# platform_designer_hps_system_hps_0_hps register map
Vendor: default_vendor.com; File version: 0.0
Registers are 32-bit, read-write, reset 0x0 unless marked. A register's access mark holds for its fields unless they carry their own. Offsets are from the block's base; [hi:lo] are bit positions; {n}, {i} and the like mark numbered series; 'fields as' and 'values as' point back to an identical list.

## qspiregs — Registers in the QSPI Flash Controller module accessible via its APB slave
Base 0xFF705000
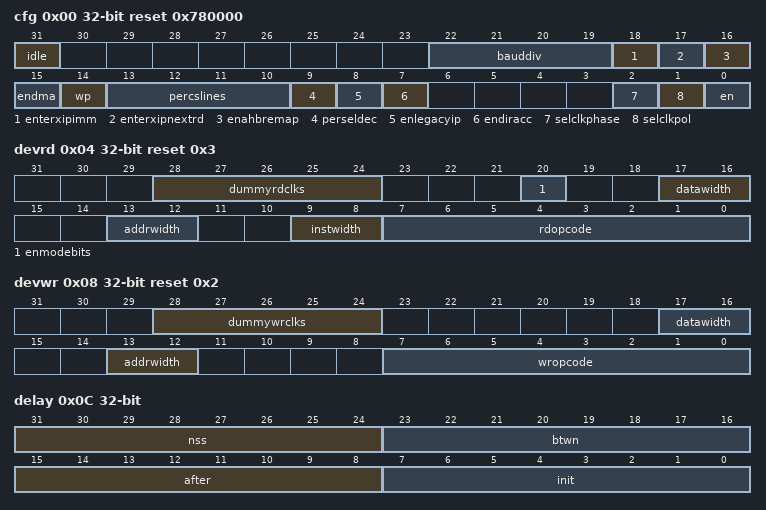
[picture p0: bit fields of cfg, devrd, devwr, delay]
0x00 cfg reset 0x780000
  [31] idle ro — This is a STATUS read-only bit. Note this is a retimed signal, so there will be some inherent delay on the generation of this status signal.
    1=set; 0=notset
  [22:19] bauddiv — SPI baud rate = ref_clk / (2 * baud_rate_divisor)
    0=baud2; 1=baud4; 2=baud6; 3=baud8; 4=baud10; 5=baud12; 6=baud14; 7=baud16; 8=baud18; 9=baud20; 10=baud22; 11=baud24; 12=baud26; 13=baud28; 14=baud30; 15=baud32
  [18] enterxipimm — If XIP is enabled, then setting to disabled will cause the controller to exit XIP mode on the next READ instruction. If XIP is disabled, then setting enable will operate the device in XIP mode immediately. Use this register when the external device wakes up in XIP mode (as per the contents of its non- volatile configuration register). The controller will assume the next READ instruction will be passed to the device as an XIP instruction, and therefore will not require the READ opcode to be transferred. Note: To exit XIP mode, this bit should be set to 0. This will take effect in the attached device only after the next READ instruction is executed. Software therefore should ensure that at least one READ instruction is requested after resetting this bit in order to be sure that XIP mode is exited.
    1=enable; 0=disable
  [17] enterxipnextrd — If XIP is enabled, then setting to disabled will cause the controller to exit XIP mode on the next READ instruction. If XIP is disabled, then setting to enabled will inform the controller that the device is ready to enter XIP on the next READ instruction. The controller will therefore send the appropriate command sequence, including mode bits to cause the device to enter XIP mode. Use this register after the controller has ensured the FLASH device has been configured to be ready to enter XIP mode. Note : To exit XIP mode, this bit should be set to 0. This will take effect in the attached device only AFTER the next READ instruction is executed. Software should therefore ensure that at least one READ instruction is requested after resetting this bit before it can be sure XIP mode in the device is exited.
    1=enable; 0=disable
  [16] enahbremap — (Direct Access Mode Only) When enabled, the incoming AHB address will be adapted and sent to the FLASH device as (address + N), where N is the value stored in the remap address register.
    1=enable; 0=disable
  [15] endma — Allows DMA handshaking mode. When enabled the QSPI will trigger DMA transfer requests via the DMA peripheral interface.
    1=enable; 0=disable
  [14] wp — This bit controls the write protect pin of the flash devices. The signal qspi_mo2_wpn needs to be resynchronized to the generated memory clock as necessary.
    1=wrproton; 0=wrtprotoff
  [13:10] percslines — Peripheral chip select line output decode type. As per perseldec, if perseldec = 0, the decode is select 1 of 4 decoding on signals, qspi_n_ss_out[3:0], The asserted decode line goes to 0. If perseldec = 1, the signals qspi_n_ss_out[3:0] require an external 4 to 16 decoder.
  [9] perseldec — Select between '1 of 4 selects' or 'external 4-to-16 decode'. The qspi_n_ss_out[3:0] output signals are controlled.
    1=sel4to16; 0=sel1of4
  [8] enlegacyip — This bit can select the Direct Access Controller/Indirect Access Controller or legacy mode.If legacy mode is selected, any write to the controller via the AHB interface is serialized and sent to the FLASH device. Any valid AHB read will pop the internal RX-FIFO, retrieving data that was forwarded by the external FLASH device on the SPI lines, byte transfers of 4, 2 or 1 are permitted and controlled via the HSIZE input.
    1=legmode; 0=dimode
  [7] endiracc — If disabled, the Direct Access Controller becomes inactive once the current transfer of the data word (FF_W) is complete. When the Direct Access Controller and Indirect Access Controller are both disabled, all AHB requests are completed with an error response.
    0=disable; 1=enable
  [2] selclkphase — Selects whether the clock is in an active or inactive phase outside the SPI word.
    0=active; 1=inactive
  [1] selclkpol — Controls spiclk modes of operation.
    1=low; 0=high
  [0] en — If this bit is disabled, the QSPI will finish the current transfer of the data word (FF_W) and stop sending. When Enabled, and qspi_n_mo_en = 0, all output enables are inactive and all pins are set to input mode.
    0=disable; 1=enable
0x04 devrd reset 0x3
  [28:24] dummyrdclks — Number of dummy clock cycles required by device for read instruction.
  [20] enmodebits — If this bit is set, the mode bits as defined in the Mode Bit Configuration register are sent following the address bytes.
    0=noorder; 1=order
  [17:16] datawidth — Sets read data transfer width (1, 2, or 4 bits).
    0=single; 1=dual; 2=quad
  [13:12] addrwidth — Sets read address transfer width (1, 2, or 4 bits).
    0=single; 1=dual; 2=quad
  [9:8] instwidth — Sets instruction transfer width (1, 2, or 4 bits). Applies to all instructions sent to SPI flash device (not just read instructions).
    0=single; 1=dual; 2=quad
  [7:0] rdopcode — Read Opcode to use when not in XIP mode
    3=read; 11=fastread
0x08 devwr reset 0x2
  [28:24] dummywrclks — Number of dummy clock cycles required by device for write instruction.
  [17:16] datawidth — Sets write data transfer width (1, 2, or 4 bits).
    0=single; 1=dual; 2=quad
  [13:12] addrwidth — Sets write address transfer width (1, 2, or 4 bits).
    0=single; 1=dual; 2=quad
  [7:0] wropcode — Write Opcode
0x0C delay — This register is used to introduce relative delays into the generation of the master output signals. All timings are defined in cycles of the qspi_clk.
  [31:24] nss — Delay in master reference clocks for the length that the master mode chip select outputs are de-asserted between transactions. The minimum delay is always qspi_sck_out period to ensure the chip select is never re-asserted within an qspi_sck_out period.
  [23:16] btwn — Delay in master reference clocks between one chip select being de-activated and the activation of another. This is used to ensure a quiet period between the selection of two different slaves and requires the transmit FIFO to be empty.
  [15:8] after — Delay in master reference clocks between last bit of current transaction and deasserting the device chip select (qspi_n_ss_out). By default, the chip select will be deasserted on the cycle following the completion of the current transaction.
  [7:0] init — Delay in master reference clocks between setting qspi_n_ss_out low and first bit transfer.
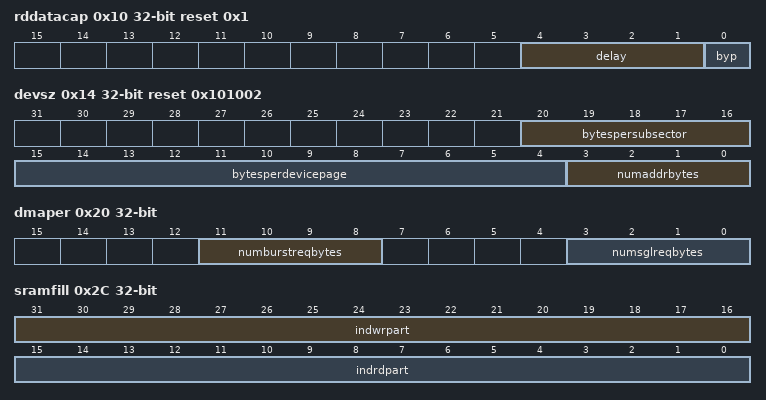
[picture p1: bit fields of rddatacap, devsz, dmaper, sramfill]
0x10 rddatacap reset 0x1
  [4:1] delay — Delay the read data capturing logic by the programmed number of qspi_clk cycles
  [0] byp — Controls bypass of the adapted loopback clock circuit
    0=nobypass; 1=bypass
0x14 devsz reset 0x101002
  [20:16] bytespersubsector — Number of bytes per Block. This is required by the controller for performing the write protection logic. The number of bytes per block must be a power of 2 number.
  [15:4] bytesperdevicepage — Number of bytes per device page. This is required by the controller for performing FLASH writes up to and across page boundaries.
  [3:0] numaddrbytes — Number of address bytes. A value of 0 indicates 1 byte.
0x18 srampart reset 0x40
  [6:0] addr — Defines the size of the indirect read partition in the SRAM, in units of SRAM locations. By default, half of the SRAM is reserved for indirect read operations and half for indirect write operations.
0x1C indaddrtrig
  [31:0] addr — This is the base address that will be used by the AHB controller. When the incoming AHB read access address matches a range of addresses from this trigger address to the trigger address + 15, then the AHB request will be completed by fetching data from the Indirect Controllers SRAM.
0x20 dmaper
  [11:8] numburstreqbytes — Number of bytes in a burst type request on the DMA peripheral request. A programmed value of 0 represents a single byte. This should be setup before starting the indirect read or write operation. The actual number of bytes used is 2**(value in this register) which will simplify implementation.
  [3:0] numsglreqbytes — Number of bytes in a single type request on the DMA peripheral request. A programmed value of 0 represents a single byte. This should be setup before starting the indirect read or write operation. The actual number of bytes used is 2**(value in this register) which will simplify implementation.
0x24 remapaddr — This register is used to remap an incoming AHB address to a different address used by the FLASH device.
  [31:0] value — This offset is added to the incoming AHB address to determine the address used by the FLASH device.
0x28 modebit
  [7:0] mode — These are the 8 mode bits that are sent to the device following the address bytes if mode bit transmission has been enabled.
0x2C sramfill ro
  [31:16] indwrpart, [15:0] indrdpart
0x30 txthresh reset 0x1
  [3:0] level — Defines the level at which the transmit FIFO not full interrupt is generated
0x34 rxthresh reset 0x1 — Device Instruction Register
  [3:0] level — Defines the level at which the receive FIFO not empty interrupt is generated
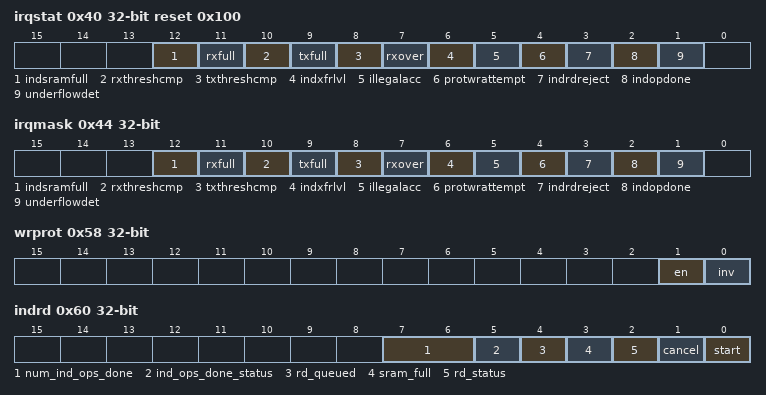
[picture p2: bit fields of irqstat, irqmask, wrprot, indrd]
0x40 irqstat reset 0x100 — The status fields in this register are set when the described event occurs and the interrupt is enabled in the mask register. When any of these bit fields are set, the interrupt output is asserted high. The fields are each cleared by writing a 1 to the field. Note that bit fields 7 thru 11 are only valid when legacy SPI mode is active.
  [12] indsramfull write-1-clears — Indirect Read Partition of SRAM is full and unable to immediately complete indirect operation
    1=rdpartfull; 0=rdpartnotfull
  [11] rxfull write-1-clears — Indicates that the receive FIFO is full or not. Only relevant in SPI legacy mode.
    0=notfull; 1=full
  [10] rxthreshcmp write-1-clears — Indicates the number of entries in the receive FIFO with respect to the threshold specified in the RXTHRESH register. Only relevant in SPI legacy mode.
    0=le; 1=gt
  [9] txfull write-1-clears — Indicates that the transmit FIFO is full or not. Only relevant in SPI legacy mode.
    0=notfull; 1=full
  [8] txthreshcmp write-1-clears — Indicates the number of entries in the transmit FIFO with respect to the threshold specified in the TXTHRESH register. Only relevant in SPI legacy mode.
    0=gt; 1=le
  [7] rxover write-1-clears — This should only occur in Legacy SPI mode. Set if an attempt is made to push the RX FIFO when it is full. This bit is reset only by a system reset and cleared only when this register is read. If a new push to the RX FIFO occurs coincident with a register read this flag will remain set. 0 : no overflow has been detected. 1 : an overflow has occurred.
    1=rcvover; 0=norcvover
  [6] indxfrlvl write-1-clears — Indirect Transfer Watermark Level Reached
    1=waterlevl; 0=nowaterlvl
  [5] illegalacc write-1-clears — Illegal AHB access has been detected. AHB wrapping bursts and the use of SPLIT/RETRY accesses will cause this error interrupt to trigger.
    1=illegalahb; 0=noillegalahb
  [4] protwrattempt write-1-clears — Write to protected area was attempted and rejected.
    1=writeprot; 0=nowriteprot
  [3] indrdreject write-1-clears — Indirect operation was requested but could not be accepted. Two indirect operations already in storage.
    1=indirectreq; 0=noindirectreq
  [2] indopdone write-1-clears — Controller has completed last triggered indirect operation
    1=indirectop; 0=noindirectop
  [1] underflowdet write-1-clears — An underflow is detected when an attempt to transfer data is made when the transmit FIFO is empty. This may occur when the AHB write data is being supplied too slowly to keep up with the requested write operation. This bit is reset only by a system reset and cleared only when the register is read.
    1=underflow; 0=nounderflow
0x44 irqmask — If disabled, the interrupt for the corresponding interrupt status register bit is disabled. If enabled, the interrupt for the corresponding interrupt status register bit is enabled.
  [all] fields
    0=disabled; 1=enabled
  [12] indsramfull
  [11] rxfull
  [10] rxthreshcmp
  [9] txfull
  [8] txthreshcmp
  [7] rxover
  [6] indxfrlvl
  [5] illegalacc
  [4] protwrattempt
  [3] indrdreject
  [2] indopdone
  [1] underflowdet
0x50 lowwrprot
  [31:0] subsector — The block number that defines the lower block in the range of blocks that is to be locked from writing. The definition of a block in terms of number of bytes is programmable via the Device Size Configuration register.
0x54 uppwrprot
  [31:0] subsector — The block number that defines the upper block in the range of blocks that is to be locked from writing. The definition of a block in terms of number of bytes is programmable via the Device Size Configuration register.
0x58 wrprot
  [1] en — When enabled, any AHB write access with an address within the protection region defined in the lower and upper write protection registers is rejected. An AHB error response is generated and an interrupt source triggered. When disabled, the protection region is disabled.
    1=enable; 0=disable
  [0] inv — When enabled, the protection region defined in the lower and upper write protection registers is inverted meaning it is the region that the system is permitted to write to. When disabled, the protection region defined in the lower and upper write protection registers is the region that the system is not permitted to write to.
    1=enable; 0=disable
0x60 indrd (reset mask 0xFFFFFF03)
  [7:6] num_ind_ops_done ro — This field contains the number of indirect operations which have been completed. This is used in conjunction with the indirect completion status field (bit 5).
  [5] ind_ops_done_status write-1-clears — This field is set to 1 when an indirect operation has completed. Write a 1 to this field to clear it.
    1=indcomp; 0=noaction
  [4] rd_queued ro — Two indirect read operations have been queued
    1=quindirectrd; 0=noaction
  [3] sram_full write-1-clears — SRAM full and unable to immediately complete an indirect operation. Write a 1 to this field to clear it. ; indirect operation (status)
    1=sramfull; 0=noaction
  [2] rd_status ro — Indirect read operation in progress (status)
    1=readop; 0=noaction
  [1] cancel — This bit will cancel all ongoing indirect read operations.
    1=cancel; 0=noaction
  [0] start — When this bit is enabled, it will trigger an indirect read operation. The assumption is that the indirect start address and the indirect number of bytes register is setup before triggering the indirect read operation.
    1=enabled; 0=disabled
0x64 indrdwater
  [31:0] level — This represents the minimum fill level of the SRAM before a DMA peripheral access is permitted. When the SRAM fill level passes the watermark, an interrupt is also generated. This field can be disabled by writing a value of all zeroes. The units of this register are BYTES
0x68 indrdstaddr
  [31:0] addr — This is the start address from which the indirect access will commence its READ operation.
0x6C indrdcnt
  [31:0] value — This is the number of bytes that the indirect access will consume. This can be bigger than the configured size of SRAM.
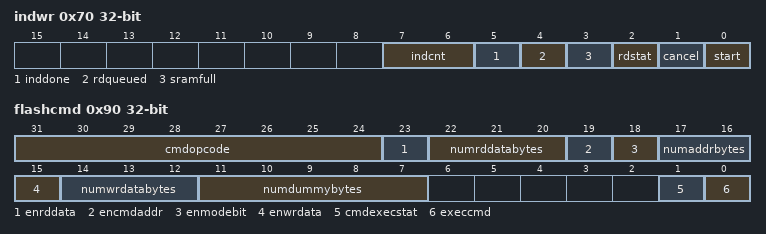
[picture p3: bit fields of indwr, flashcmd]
0x70 indwr (reset mask 0xFFFFFF0B)
  [7:6] indcnt ro — This field contains the count of indirect operations which have been completed. This is used in conjunction with the indirect completion status field (bit 5).
  [5] inddone write-1-clears — This field is set to 1 when an indirect operation has completed. Write a 1 to this field to clear it.
    1=indcompst; 0=noaction
  [4] rdqueued ro — Two indirect write operations have been queued
    1=indwrop; 0=noaction
  [3] sramfull ro
  [2] rdstat ro — Indirect write operation in progress (status)
    1=indwrstat; 0=noaction
  [1] cancel — Writing a 1 to this bit will cancel all ongoing indirect write operations.
    1=canceindwr; 0=noaction
  [0] start — Writing a 1 to this bit will trigger an indirect write operation. The assumption is that the indirect start address and the indirect number of bytes register is setup before triggering the indirect write operation.
    1=enabled; 0=disabled
0x74 indwrwater reset 0xFFFFFFFF
  [31:0] level — This represents the maximum fill level of the SRAM before a DMA peripheral access is permitted. When the SRAM fill level falls below the watermark, an interrupt is also generated. This field can be disabled by writing a value of all ones. The units of this register are bytes.
0x78 indwrstaddr
  [31:0] addr — This is the start address from which the indirect access will commence its write operation.
0x7C indwrcnt
  fields as indrdcnt
0x90 flashcmd
  [31:24] cmdopcode — The command opcode field should be setup before triggering the command. For example, 0x20 maps to SubSector Erase. Writeing to the execute field (bit 0) of this register launches the command. NOTE : Using this approach to issue commands to the device will make use of the instruction type of the device instruction configuration register. If this field is set to 2'b00, then the command opcode, command address, command dummy bytes and command data will all be transferred in a serial fashion. If this field is set to 2'b01, then the command opcode, command address, command dummy bytes and command data will all be transferred in parallel using DQ0 and DQ1 pins. If this field is set to 2'b10, then the command opcode, command address, command dummy bytes and command data will all be transferred in parallel using DQ0, DQ1, DQ2 and DQ3 pins.
  [23] enrddata — If enabled, the command specified in the command opcode field (bits 31:24) requires read data bytes to be received from the device.
    1=enable; 0=noaction
  [22:20] numrddatabytes — Up to 8 data bytes may be read using this command. Set to 0 for 1 byte and 7 for 8 bytes.
    {v}=rdbyte{v+1} (v=0..7)
  [19] encmdaddr — If enabled, the command specified in bits 31:24 requires an address. This should be setup before triggering the command via writing a 1 to the execute field.
    1=enabled; 0=disabled
  [18] enmodebit — Set to 1 to ensure the mode bits as defined in the Mode Bit Configuration register are sent following the address bytes.
    1=enabled; 0=disabled
  [17:16] numaddrbytes — Set to the number of address bytes required (the address itself is programmed in the FLASH COMMAND ADDRESS REGISTERS). This should be setup before triggering the command via bit 0 of this register. 2'b00 : 1 address byte 2'b01 : 2 address bytes 2'b10 : 3 address bytes 2'b11 : 4 address bytes
    {v}=addrbyte{v+1} (v=0..3)
  [15] enwrdata — Set to 1 if the command specified in the command opcode field requires write data bytes to be sent to the device.
    1=wrdatabytes; 0=noaction
  [14:12] numwrdatabytes — Up to 8 Data bytes may be written using this command.
    {v}=wrbyte{v+1} (v=0..7)
  [11:7] numdummybytes — Set to the number of dummy bytes required This should be setup before triggering the command via the execute field of this register.
  [1] cmdexecstat ro — Command execution in progress.
    1=executestat; 0=noaction
  [0] execcmd — Execute the command.
    1=execute; 0=noaction
0x94 flashcmdaddr
  [31:0] addr — This should be setup before triggering the command with execute field (bit 0) of the Flash Command Control register. It is the address used by the command specified in the opcode field (bits 31:24) of the Flash Command Control register.
0xA0 flashcmdrddatalo
  [31:0] data — This is the data that is returned by the flash device for any status or configuration read operation carried out by triggering the event in the control register. The register will be valid when the polling bit in the control register is low.
0xA4 flashcmdrddataup — Device Instruction Register
  [31:0] data — This is the data that is returned by the FLASH device for any status or configuration read operation carried out by triggering the event in the control register. The register will be valid when the polling bit in the control register is low.
0xA8 flashcmdwrdatalo
  [31:0] data — This is the command write data lower byte. This should be setup before triggering the command with execute field (bit 0) of the Flash Command Control register. It is the data that is to be written to the flash for any status or configuration write operation carried out by triggering the event in the Flash Command Control register.
0xAC flashcmdwrdataup
  [31:0] data — This is the command write data upper byte. This should be setup before triggering the command with execute field (bit 0) of the Flash Command Control register. It is the data that is to be written to the flash for any status or configuration write operation carried out by triggering the event in the Flash Command Control register.
0xFC moduleid ro reset 0x1001
  [24:0] value
